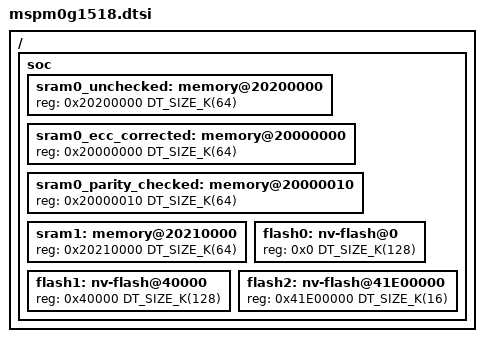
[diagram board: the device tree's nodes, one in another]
/* SPDX-License-Identifier: Apache-2.0 */

#include <mem.h>
#include <ti/mspm0/g/mspm0gx51x.dtsi>

/ {
	soc {
		/*
		* SRAM Bank 0 has optional ECC or Parity checking 
		* SRAM0 ECC Corrected: 0x2000.0000
		* SRAM0 Parity Checked: 0x2010.0000
		* SRAM0 Unchecked: 0x2020.0000
		* Sram Bank 1 (sram1) is only available as unchecked 
		*/
		sram0_unchecked: memory@20200000 {
			reg = <0x20200000 DT_SIZE_K(64)>;
		};

		sram0_ecc_corrected: memory@20000000 {
			reg = <0x20000000 DT_SIZE_K(64)>;
		};

		sram0_parity_checked: memory@20000010 {
			reg = <0x20000010 DT_SIZE_K(64)>;
		};

        sram1: memory@20210000 {
            reg = <0x20210000 DT_SIZE_K(64)>;
        };

		flash0: nv-flash@0 {
			reg = <0x0 DT_SIZE_K(128)>;
		};

		flash1: nv-flash@40000 {
			reg = <0x40000 DT_SIZE_K(128)>;
		};

		flash2: nv-flash@41E00000 {
			reg = <0x41E00000 DT_SIZE_K(16)>;
		};
	};
};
